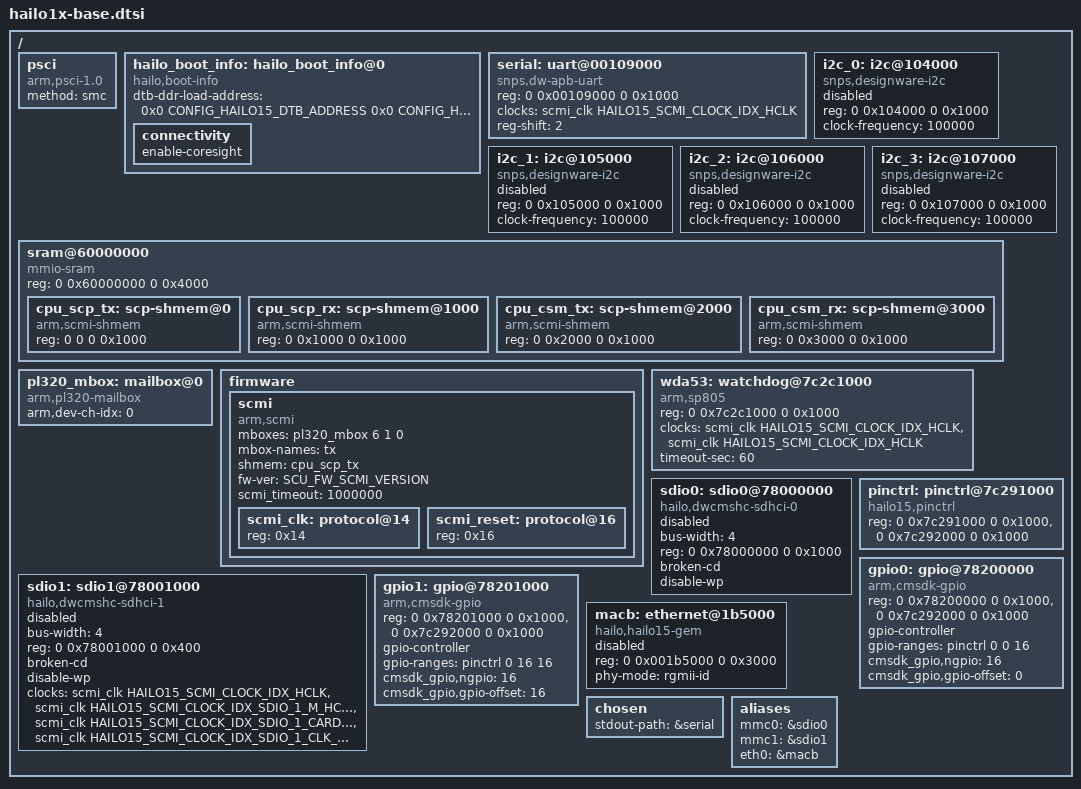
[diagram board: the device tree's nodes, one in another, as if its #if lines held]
// SPDX-License-Identifier: GPL-2.0
/*
 * dts file for Hailo Hailo15 SoC
 *
 * Copyright (c) 2019-2023 Hailo Technologies Ltd. All rights reserved.
 */

/dts-v1/;

#include <generated/autoconf.h>
#include <dt-bindings/soc/hailo15_scu_fw_version.h>
#include <dt-bindings/soc/hailo15_scmi_api.h>
#include <dt-bindings/soc/hailo1x_product.h>

/* reserved memory for platform scratch page */
/memreserve/ 0x800FF000 0x0001000;
/* reserved memory for linux device tree and overlay */
/memreserve/ 0x80800000 0x100000;
/* reserved memory for u-boot devicetree boot */
/memreserve/ CONFIG_HAILO15_DTB_ADDRESS CONFIG_HAILO15_DTB_MAX_SIZE;
/* reserved memory for pre-console buffer */
/memreserve/ CONFIG_PRE_CON_BUF_ADDR CONFIG_PRE_CON_BUF_SZ;
/* reserved memory for logs used by linux */
/memreserve/ 0x80200000 0xFE000;

/ {
    #address-cells = <2>;
    #size-cells = <2>;

    psci {
        compatible = "arm,psci-1.0";
        method = "smc";
    };

    hailo_boot_info: hailo_boot_info@0 {
        compatible = "hailo,boot-info";
        dtb-ddr-load-address = <0x0 CONFIG_HAILO15_DTB_ADDRESS 0x0 CONFIG_HAILO15_DTB_MAX_SIZE>;

#ifdef CONFIG_HAILO15_ENABLE_CORESIGHT_AT_BOOT
        connectivity {
            enable-coresight;
        };
#endif
        // soc-turbo-mode = "nn-optimized";
    };

    serial: uart@00109000 {
        compatible = "snps,dw-apb-uart";
        reg = <0 0x00109000 0 0x1000>;
        clocks = <&scmi_clk HAILO15_SCMI_CLOCK_IDX_HCLK>;
        clock-names = "hclk";
        reg-shift = <2>;
        u-boot,dm-spl;
    };

    i2c_0: i2c@104000 {
        status = "disabled";
        compatible = "snps,designware-i2c";
        reg = <0 0x104000 0 0x1000>;
        clock-frequency = <100000>;
        clock-names = "hclk";
        #address-cells = <1>;
        #size-cells = <0>;
    };

    i2c_1: i2c@105000 {
        status = "disabled";
        compatible = "snps,designware-i2c";
        reg = <0 0x105000 0 0x1000>;
        clock-frequency = <100000>;
        clock-names = "hclk";
        #address-cells = <1>;
        #size-cells = <0>;
    };

    i2c_2: i2c@106000 {
        status = "disabled";
        compatible = "snps,designware-i2c";
        reg = <0 0x106000 0 0x1000>;
        clock-frequency = <100000>;
        clock-names = "hclk";
        #address-cells = <1>;
        #size-cells = <0>;
    };

    i2c_3: i2c@107000 {
        status = "disabled";
        compatible = "snps,designware-i2c";
        reg = <0 0x107000 0 0x1000>;
        clock-frequency = <100000>;
        clock-names = "hclk";
        #address-cells = <1>;
        #size-cells = <0>;
    };

    sram@60000000 {
        compatible = "mmio-sram";
        reg = <0 0x60000000 0 0x4000>;

        #address-cells = <2>;
        #size-cells = <2>;
        ranges = <0x0 0x0 0x0 0x60000000 0x0 0x4000>;

        u-boot,dm-spl;
        cpu_scp_tx: scp-shmem@0 {
            compatible = "arm,scmi-shmem";
            reg = <0 0 0 0x1000>;
            u-boot,dm-spl;
        };
        cpu_scp_rx: scp-shmem@1000 {
            compatible = "arm,scmi-shmem";
            reg = <0 0x1000 0 0x1000>;
        };
        cpu_csm_tx: scp-shmem@2000 {
            compatible = "arm,scmi-shmem";
            reg = <0 0x2000 0 0x1000>;
        };
        cpu_csm_rx: scp-shmem@3000 {
            compatible = "arm,scmi-shmem";
            reg = <0 0x3000 0 0x1000>;
        };
    };

    pl320_mbox: mailbox@0 {
        #mbox-cells = <3>;
        compatible = "arm,pl320-mailbox";
        arm,dev-ch-idx = <0>;
        u-boot,dm-spl;
    };

    firmware {
        scmi {
            compatible = "arm,scmi";
            mboxes = <&pl320_mbox 6 1 0>;
            mbox-names = "tx";
            shmem = <&cpu_scp_tx>;
            #address-cells = <1>;
            #size-cells = <0>;
            fw-ver = <SCU_FW_SCMI_VERSION>;
            scmi_timeout = <1000000>;
            u-boot,dm-spl;
            scmi_clk: protocol@14 {
                reg = <0x14>;
                #clock-cells = <1>;
                u-boot,dm-spl;
            };
            scmi_reset: protocol@16 {
                reg = <0x16>;
                #reset-cells = <1>;
                u-boot,dm-spl;
            };
        };
    };

    wda53: watchdog@7c2c1000 {
        compatible = "arm,sp805", "arm,primecell";
        reg = <0 0x7c2c1000 0 0x1000>;
                clocks = <&scmi_clk HAILO15_SCMI_CLOCK_IDX_HCLK>, <&scmi_clk HAILO15_SCMI_CLOCK_IDX_HCLK>;
        clock-names = "wdog_clk", "apb_pclk";
                timeout-sec = <60>;
        u-boot,dm-spl;
    };

    sdio0: sdio0@78000000 {
        status = "disabled";
        compatible = "hailo,dwcmshc-sdhci-0";
        bus-width = <4>;
        reg = <0 0x78000000 0 0x1000>;
        broken-cd;
        disable-wp;
        u-boot,dm-spl;
    };
    sdio1: sdio1@78001000 {
        status = "disabled";
        compatible = "hailo,dwcmshc-sdhci-1";
        bus-width = <4>;
        reg = <0 0x78001000 0 0x400>;
        broken-cd;
        disable-wp;
        clocks = <&scmi_clk HAILO15_SCMI_CLOCK_IDX_HCLK>, <&scmi_clk HAILO15_SCMI_CLOCK_IDX_SDIO_1_M_HCLK>,
                 <&scmi_clk HAILO15_SCMI_CLOCK_IDX_SDIO_1_CARD_CLK>, <&scmi_clk HAILO15_SCMI_CLOCK_IDX_SDIO_1_CLK_DIV_BYPASS>;
        clock-names = "core", "m_clk", "card_clk", "clk_div_bypass";
        u-boot,dm-spl;
    };

    pinctrl: pinctrl@7c291000 {
        compatible = "hailo15,pinctrl";
        reg = <0 0x7c291000 0 0x1000>,
              <0 0x7c292000 0 0x1000>;
        reg-names = "general_pads_config_base", "gpio_pads_config_base";
    };

    gpio0: gpio@78200000 {
        compatible = "arm,cmsdk-gpio";
        reg = <0 0x78200000 0 0x1000>,
              <0 0x7c292000 0 0x1000>;
        gpio-controller;
        gpio-ranges = <&pinctrl 0 0 16>;
        #gpio-cells = <2>;
        cmsdk_gpio,ngpio = <16>;
        cmsdk_gpio,gpio-offset = <0>;
    };

    gpio1: gpio@78201000 {
        compatible = "arm,cmsdk-gpio";
        reg = <0 0x78201000 0 0x1000>,
              <0 0x7c292000 0 0x1000>;
        gpio-controller;
        gpio-ranges = <&pinctrl 0 16 16>;
        #gpio-cells = <2>;
        cmsdk_gpio,ngpio = <16>;
        cmsdk_gpio,gpio-offset = <16>;
    };

    macb: ethernet@1b5000 {
        status = "disabled";
        compatible = "hailo,hailo15-gem";
        reg = <0 0x001b5000 0 0x3000>;
        reg-names = "eth_ctrl";
        phy-mode = "rgmii-id";
    };
    chosen {
        stdout-path = &serial;
    };

    aliases {
        mmc0 = &sdio0;
        mmc1 = &sdio1;
        eth0 = &macb;
    };
};
